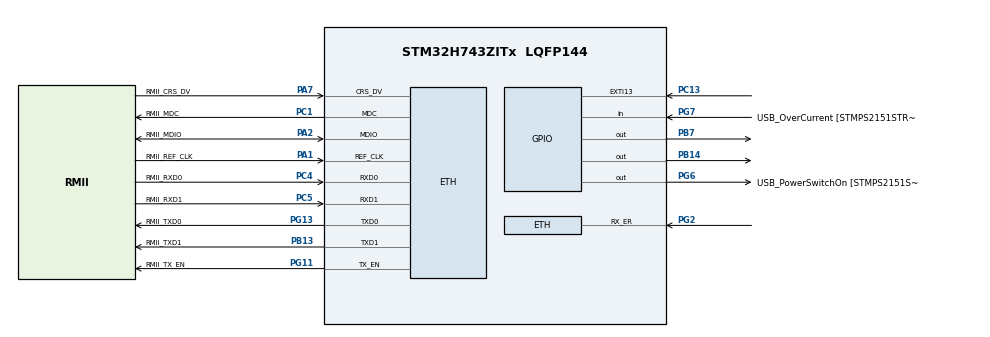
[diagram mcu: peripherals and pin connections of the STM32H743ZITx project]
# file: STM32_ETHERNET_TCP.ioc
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CORTEX_M7.AccessPermission-Cortex_Memory_Protection_Unit_Region0_Settings=MPU_REGION_NO_ACCESS
CORTEX_M7.AccessPermission-Cortex_Memory_Protection_Unit_Region1_Settings=MPU_REGION_FULL_ACCESS
CORTEX_M7.BaseAddress-Cortex_Memory_Protection_Unit_Region0_Settings=0x00000000
CORTEX_M7.BaseAddress-Cortex_Memory_Protection_Unit_Region1_Settings=0x30000000
CORTEX_M7.CPU_DCache=Disabled
CORTEX_M7.CPU_ICache=Disabled
CORTEX_M7.DisableExec-Cortex_Memory_Protection_Unit_Region0_Settings=MPU_INSTRUCTION_ACCESS_DISABLE
CORTEX_M7.DisableExec-Cortex_Memory_Protection_Unit_Region1_Settings=MPU_INSTRUCTION_ACCESS_DISABLE
CORTEX_M7.Enable-Cortex_Memory_Protection_Unit_Region0_Settings=MPU_REGION_ENABLE
CORTEX_M7.Enable-Cortex_Memory_Protection_Unit_Region1_Settings=MPU_REGION_ENABLE
CORTEX_M7.IsBufferable-Cortex_Memory_Protection_Unit_Region0_Settings=MPU_ACCESS_NOT_BUFFERABLE
CORTEX_M7.IsBufferable-Cortex_Memory_Protection_Unit_Region1_Settings=MPU_ACCESS_NOT_BUFFERABLE
CORTEX_M7.IsCacheable-Cortex_Memory_Protection_Unit_Region0_Settings=MPU_ACCESS_NOT_CACHEABLE
CORTEX_M7.IsCacheable-Cortex_Memory_Protection_Unit_Region1_Settings=MPU_ACCESS_NOT_CACHEABLE
CORTEX_M7.IsShareable-Cortex_Memory_Protection_Unit_Region0_Settings=MPU_ACCESS_SHAREABLE
CORTEX_M7.IsShareable-Cortex_Memory_Protection_Unit_Region1_Settings=MPU_ACCESS_SHAREABLE
CORTEX_M7.MPU_Control=MPU_PRIVILEGED_DEFAULT
CORTEX_M7.Size-Cortex_Memory_Protection_Unit_Region0_Settings=MPU_REGION_SIZE_4GB
CORTEX_M7.Size-Cortex_Memory_Protection_Unit_Region1_Settings=MPU_REGION_SIZE_64KB
CORTEX_M7.SubRegionDisable-Cortex_Memory_Protection_Unit_Region0_Settings=0x87
CORTEX_M7.SubRegionDisable-Cortex_Memory_Protection_Unit_Region1_Settings=0x00
CORTEX_M7.TypeExtField-Cortex_Memory_Protection_Unit_Region0_Settings=MPU_TEX_LEVEL0
CORTEX_M7.TypeExtField-Cortex_Memory_Protection_Unit_Region1_Settings=MPU_TEX_LEVEL1
CORTEX_M7.default_mode_Activation=1
ETH.ETH_RX_DESC_CNT=4
ETH.ETH_TX_DESC_CNT=4
ETH.MACAddr=00\:80\:E1\:00\:00\:00
ETH.MediaInterface=HAL_ETH_RMII_MODE
ETH.RxBuffAddress=0x30000100
ETH.RxBuffLen=1536
ETH.RxDescAddress=0x30000000
ETH.TxDescAddress=0x30000080
FREERTOS.Tasks01=defaultTask,24,1024,StartDefaultTask,Default,NULL,Dynamic,NULL,NULL
FREERTOS.configGENERATE_RUN_TIME_STATS=1
FREERTOS.configMINIMAL_STACK_SIZE=1024
FREERTOS.configTOTAL_HEAP_SIZE=65536
FREERTOS.configUSE_NEWLIB_REENTRANT=1
FREERTOS.configUSE_STATS_FORMATTING_FUNCTIONS=1
LWIP.BSP.number=1
LWIP.DEFAULT_THREAD_STACKSIZE=1024
LWIP.GATEWAY_ADDRESS=192.168.000.001
LWIP.IP_ADDRESS=192.168.000.200
LWIP.LWIP_DHCP=0
LWIP.LWIP_NETIF_LINK_CALLBACK=1
LWIP.LWIP_RAM_HEAP_POINTER=0x30008000
LWIP.MEM_SIZE=16384
LWIP.NETMASK_ADDRESS=255.255.255.000
LWIP.TCPIP_THREAD_STACKSIZE=4096
LWIP.TCP_SND_QUEUELEN=9
LWIP.Version=v2.2.1_Cube
LWIP0.BSP.STBoard=false
LWIP0.BSP.api=BSP_COMPONENT_DRIVER
LWIP0.BSP.component=LAN8742
LWIP0.BSP.instance=LAN8742
LWIP0.BSP.name=Driver_PHY
LWIP0.BSP.semaphore=S_LAN8742
LWIP0.BSP.solution=LAN8742
Mcu.Family=STM32H7
Mcu.Name=STM32H743ZITx
Mcu.Package=LQFP144
NUCLEO-H743ZI.BUTTON=1
NUCLEO-H743ZI.LD1=true
NUCLEO-H743ZI.LD2=true
NUCLEO-H743ZI.LD3=true
NUCLEO-H743ZI.VCP=true
NVIC.EXTI15_10_IRQn=true\:5\:0\:false\:false\:true\:true\:false\:true\:true
NVIC.PriorityGroup=NVIC_PRIORITYGROUP_4
NVIC.TIM17_IRQn=true\:15\:0\:false\:false\:true\:false\:false\:true\:true
NVIC.TimeBase=TIM17_IRQn
NVIC.TimeBaseIP=TIM17
PA1.GPIO_Label=RMII_REF_CLK
PA1.Mode=RMII
PA1.Signal=ETH_REF_CLK
PA10.GPIO_Label=USB_ID
PA10.Signal=USB_OTG_FS_ID
PA11.GPIO_Label=USB_DM
PA11.Signal=USB_OTG_FS_DM
PA12.GPIO_Label=USB_DP
PA12.Signal=USB_OTG_FS_DP
PA13\ (JTMS/SWDIO).GPIO_Label=TMS
PA13\ (JTMS/SWDIO).Signal=DEBUG_JTMS-SWDIO
PA14\ (JTCK/SWCLK).GPIO_Label=TCK
PA14\ (JTCK/SWCLK).Signal=DEBUG_JTCK-SWCLK
PA2.GPIO_Label=RMII_MDIO
PA2.Mode=RMII
PA2.Signal=ETH_MDIO
PA7.GPIO_Label=RMII_CRS_DV
PA7.Mode=RMII
PA7.Signal=ETH_CRS_DV
PA8.GPIO_Label=USB_SOF [TP1]
PA8.Signal=USB_OTG_FS_SOF
PA9.GPIO_Label=USB_VBUS
PA9.Signal=USB_OTG_FS_VBUS
PB13.GPIO_Label=RMII_TXD1
PB13.Mode=RMII
PB13.Signal=ETH_TXD1
PB14.Signal=GPIO_Output
PB3\ (JTDO/TRACESWO).GPIO_Label=SWO
PB3\ (JTDO/TRACESWO).Signal=DEBUG_JTDO-SWO
PB7.Signal=GPIO_Output
PC1.GPIO_Label=RMII_MDC
PC1.Mode=RMII
PC1.Signal=ETH_MDC
PC13.Signal=GPXTI13
PC14-OSC32_IN\ (OSC32_IN).Signal=RCC_OSC32_IN
PC15-OSC32_OUT\ (OSC32_OUT).Signal=RCC_OSC32_OUT
PC4.GPIO_Label=RMII_RXD0
PC4.Mode=RMII
PC4.Signal=ETH_RXD0
PC5.GPIO_Label=RMII_RXD1
PC5.Mode=RMII
PC5.Signal=ETH_RXD1
PD8.Signal=USART3_TX
PD9.Signal=USART3_RX
PG11.GPIO_Label=RMII_TX_EN
PG11.Mode=RMII
PG11.Signal=ETH_TX_EN
PG13.GPIO_Label=RMII_TXD0
PG13.Mode=RMII
PG13.Signal=ETH_TXD0
PG2.Mode=RMII
PG2.Signal=ETH_RX_ER
PG6.GPIO_Label=USB_PowerSwitchOn [STMPS2151STR_EN]
PG6.Signal=GPIO_Output
PG7.GPIO_Label=USB_OverCurrent [STMPS2151STR_FAULT]
PG7.Signal=GPIO_Input
PH0-OSC_IN\ (PH0).GPIO_Label=MCO
PH0-OSC_IN\ (PH0).Signal=RCC_OSC_IN
ProjectManager.HeapSize=0x200
ProjectManager.StackSize=0x400
ProjectManager.TargetToolchain=STM32CubeIDE
RCC.48MHZClocksFreq_Value=24000000
RCC.ADCFreq_Value=129000000
RCC.AHBFreq_Value=216000000
RCC.APB1CLKDivider=RCC_HCLK_DIV4
RCC.APB1Freq_Value=120000000
RCC.APB1TimFreq_Value=108000000
RCC.APB2CLKDivider=RCC_HCLK_DIV2
RCC.APB2Freq_Value=120000000
RCC.APB2TimFreq_Value=216000000
RCC.APB3Freq_Value=120000000
RCC.APB4Freq_Value=120000000
RCC.CortexFreq_Value=480000000
RCC.D1PPRE=RCC_APB3_DIV2
RCC.D2PPRE1=RCC_APB1_DIV2
RCC.D2PPRE2=RCC_APB2_DIV2
RCC.D3PPRE=RCC_APB4_DIV2
RCC.DIVM1=4
RCC.DIVN1=60
RCC.DIVQ1=4
RCC.HCLKFreq_Value=240000000
RCC.HPRE=RCC_HCLK_DIV2
RCC.HSE_VALUE=8000000
RCC.HSI_VALUE=64000000
RCC.PLLFRACN=0
RCC.PLLM=25
RCC.PLLMUL=RCC_PLL_MUL9
RCC.PLLN=432
RCC.PLLQ=9
RCC.PRESCALERUSB=RCC_USBCLKSOURCE_PLL_DIV1_5
RCC.SYSCLKFreq_VALUE=480000000
RCC.SYSCLKSource=RCC_SYSCLKSOURCE_PLLCLK
RCC.SYSCLKSourceVirtual=RCC_SYSCLKSOURCE_PLLCLK
RCC.USBFreq_Value=240000000
RCC.VCOOutputFreq_Value=432000000
VP_FREERTOS_VS_CMSIS_V2.Mode=CMSIS_V2
VP_LWIP_VS_Enabled.Mode=Enabled
VP_MEMORYMAP_VS_MEMORYMAP.Mode=CurAppReg
VP_NUCLEO-H743ZI_VS_BSP_COMMON.Mode=COMMON
VP_SYS_VS_tim17.Mode=TIM17
board=NUCLEO-H743ZI

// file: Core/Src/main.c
/* USER CODE BEGIN Header */
/**
  ******************************************************************************
  * @file           : main.c
  * @brief          : Main program body
  ******************************************************************************
  * @attention
  *
  * Copyright (c) 2026 STMicroelectronics.
  * All rights reserved.
  *
  * This software is licensed under terms that can be found in the LICENSE file
  * in the root directory of this software component.
  * If no LICENSE file comes with this software, it is provided AS-IS.
  *
  ******************************************************************************
  */
/* USER CODE END Header */
#include "main.h"
#include "FreeRTOS.h"
#include "cmsis_os2.h"
#include "lwip.h"

/* USER CODE BEGIN Includes */
#include "led_manager.h"
#include "tcp_server.h"
#include "iec104/iec104_app.h"
/* USER CODE END Includes */

COM_InitTypeDef BspCOMInit;

/* One-shot initialization task. */
static const osThreadAttr_t initTask_attributes = {
  .name = "InitTask",
  .stack_size = 1024 * 4,
  .priority = (osPriority_t) osPriorityNormal,
};

void SystemClock_Config(void);
static void MPU_Config(void);
static void MX_GPIO_Init(void);
static void StartInitTask(void *argument);

int main(void)
{

  /* MPU Configuration--------------------------------------------------------*/
  MPU_Config();

  /* MCU Configuration--------------------------------------------------------*/

  /* Reset of all peripherals, Initializes the Flash interface and the Systick. */
  HAL_Init();

  /* Configure the system clock */
  SystemClock_Config();

  /* Initialize all configured peripherals */
  MX_GPIO_Init();

  /* Init scheduler */
  osKernelInitialize();

  /* Create the thread(s) */
  /* Create the one-shot initialization task. */
  (void)osThreadNew(StartInitTask, NULL, &initTask_attributes);

  /* Initialize leds */
  BSP_LED_Init(LED_GREEN);
  BSP_LED_Init(LED_BLUE);
  BSP_LED_Init(LED_RED);

  /* Initialize USER push-button, will be used to trigger an interrupt each time it's pressed.*/
  BSP_PB_Init(BUTTON_USER, BUTTON_MODE_EXTI);

  /* Initialize COM1 port (115200, 8 bits (7-bit data + 1 stop bit), no parity */
  BspCOMInit.BaudRate   = 115200;
  BspCOMInit.WordLength = COM_WORDLENGTH_8B;
  BspCOMInit.StopBits   = COM_STOPBITS_1;
  BspCOMInit.Parity     = COM_PARITY_NONE;
  BspCOMInit.HwFlowCtl  = COM_HWCONTROL_NONE;
  if (BSP_COM_Init(COM1, &BspCOMInit) != BSP_ERROR_NONE)
  {
    Error_Handler();
  }

  /* Start scheduler */
  osKernelStart();

  /* We should never get here as control is now taken by the scheduler */

  /* Infinite loop */
  while (1)
  {

  }
}

void SystemClock_Config(void)
{
  RCC_OscInitTypeDef RCC_OscInitStruct = {0};
  RCC_ClkInitTypeDef RCC_ClkInitStruct = {0};

  /** Supply configuration update enable
  */
  HAL_PWREx_ConfigSupply(PWR_LDO_SUPPLY);

  /** Configure the main internal regulator output voltage
  */
  __HAL_PWR_VOLTAGESCALING_CONFIG(PWR_REGULATOR_VOLTAGE_SCALE0);

  while(!__HAL_PWR_GET_FLAG(PWR_FLAG_VOSRDY)) {}

  /** Initializes the RCC Oscillators according to the specified parameters
  * in the RCC_OscInitTypeDef structure.
  */
  RCC_OscInitStruct.OscillatorType = RCC_OSCILLATORTYPE_HSI;
  RCC_OscInitStruct.HSIState = RCC_HSI_DIV1;
  RCC_OscInitStruct.HSICalibrationValue = RCC_HSICALIBRATION_DEFAULT;
  RCC_OscInitStruct.PLL.PLLState = RCC_PLL_ON;
  RCC_OscInitStruct.PLL.PLLSource = RCC_PLLSOURCE_HSI;
  RCC_OscInitStruct.PLL.PLLM = 4;
  RCC_OscInitStruct.PLL.PLLN = 60;
  RCC_OscInitStruct.PLL.PLLP = 2;
  RCC_OscInitStruct.PLL.PLLQ = 4;
  RCC_OscInitStruct.PLL.PLLR = 2;
  RCC_OscInitStruct.PLL.PLLRGE = RCC_PLL1VCIRANGE_3;
  RCC_OscInitStruct.PLL.PLLVCOSEL = RCC_PLL1VCOWIDE;
  RCC_OscInitStruct.PLL.PLLFRACN = 0;
  if (HAL_RCC_OscConfig(&RCC_OscInitStruct) != HAL_OK)
  {
    Error_Handler();
  }

  /** Initializes the CPU, AHB and APB buses clocks
  */
  RCC_ClkInitStruct.ClockType = RCC_CLOCKTYPE_HCLK|RCC_CLOCKTYPE_SYSCLK
                              |RCC_CLOCKTYPE_PCLK1|RCC_CLOCKTYPE_PCLK2
                              |RCC_CLOCKTYPE_D3PCLK1|RCC_CLOCKTYPE_D1PCLK1;
  RCC_ClkInitStruct.SYSCLKSource = RCC_SYSCLKSOURCE_PLLCLK;
  RCC_ClkInitStruct.SYSCLKDivider = RCC_SYSCLK_DIV1;
  RCC_ClkInitStruct.AHBCLKDivider = RCC_HCLK_DIV2;
  RCC_ClkInitStruct.APB3CLKDivider = RCC_APB3_DIV2;
  RCC_ClkInitStruct.APB1CLKDivider = RCC_APB1_DIV2;
  RCC_ClkInitStruct.APB2CLKDivider = RCC_APB2_DIV2;
  RCC_ClkInitStruct.APB4CLKDivider = RCC_APB4_DIV2;

  if (HAL_RCC_ClockConfig(&RCC_ClkInitStruct, FLASH_LATENCY_4) != HAL_OK)
  {
    Error_Handler();
  }
}

static void MX_GPIO_Init(void)
{
  GPIO_InitTypeDef GPIO_InitStruct = {0};

  /* GPIO Ports Clock Enable */
  __HAL_RCC_GPIOC_CLK_ENABLE();
  __HAL_RCC_GPIOH_CLK_ENABLE();
  __HAL_RCC_GPIOA_CLK_ENABLE();
  __HAL_RCC_GPIOB_CLK_ENABLE();
  __HAL_RCC_GPIOG_CLK_ENABLE();

  /*Configure GPIO pin Output Level */
  HAL_GPIO_WritePin(USB_PowerSwitchOn_GPIO_Port, USB_PowerSwitchOn_Pin, GPIO_PIN_RESET);

  /*Configure GPIO pin : USB_PowerSwitchOn_Pin */
  GPIO_InitStruct.Pin = USB_PowerSwitchOn_Pin;
  GPIO_InitStruct.Mode = GPIO_MODE_OUTPUT_PP;
  GPIO_InitStruct.Pull = GPIO_NOPULL;
  GPIO_InitStruct.Speed = GPIO_SPEED_FREQ_LOW;
  HAL_GPIO_Init(USB_PowerSwitchOn_GPIO_Port, &GPIO_InitStruct);

  /*Configure GPIO pin : USB_OverCurrent_Pin */
  GPIO_InitStruct.Pin = USB_OverCurrent_Pin;
  GPIO_InitStruct.Mode = GPIO_MODE_INPUT;
  GPIO_InitStruct.Pull = GPIO_NOPULL;
  HAL_GPIO_Init(USB_OverCurrent_GPIO_Port, &GPIO_InitStruct);

  /*Configure GPIO pins : USB_SOF_Pin USB_ID_Pin USB_DM_Pin USB_DP_Pin */
  GPIO_InitStruct.Pin = USB_SOF_Pin|USB_ID_Pin|USB_DM_Pin|USB_DP_Pin;
  GPIO_InitStruct.Mode = GPIO_MODE_AF_PP;
  GPIO_InitStruct.Pull = GPIO_NOPULL;
  GPIO_InitStruct.Speed = GPIO_SPEED_FREQ_LOW;
  GPIO_InitStruct.Alternate = GPIO_AF10_OTG1_FS;
  HAL_GPIO_Init(GPIOA, &GPIO_InitStruct);

}

/* USER CODE BEGIN Header_StartInitTask */
/**
  * @brief  Initialize application services, then terminate this task.
  * @param  argument: Not used
  * @retval None
  */
/* USER CODE END Header_StartInitTask */
static void StartInitTask(void *argument)
{
  (void)argument;
  /* Initialize networking while the scheduler is running. */
  MX_LWIP_Init();
  /* USER CODE BEGIN 5 */
  LedManager_Init();
  if (!IEC104_AppInit())
    Error_Handler();
  /* TcpServer_Init(); Port 3001 is not used while IEC-104 is active. */

  /* Initialization is complete; other tasks run independently. */
  osThreadExit();
  /* USER CODE END 5 */
}

 /* MPU Configuration */

void MPU_Config(void)
{
  MPU_Region_InitTypeDef MPU_InitStruct = {0};

  /* Disables the MPU */
  HAL_MPU_Disable();

  /** Initializes and configures the Region and the memory to be protected
  */
  MPU_InitStruct.Enable = MPU_REGION_ENABLE;
  MPU_InitStruct.Number = MPU_REGION_NUMBER0;
  MPU_InitStruct.BaseAddress = 0x0;
  MPU_InitStruct.Size = MPU_REGION_SIZE_4GB;
  MPU_InitStruct.SubRegionDisable = 0x87;
  MPU_InitStruct.TypeExtField = MPU_TEX_LEVEL0;
  MPU_InitStruct.AccessPermission = MPU_REGION_NO_ACCESS;
  MPU_InitStruct.DisableExec = MPU_INSTRUCTION_ACCESS_DISABLE;
  MPU_InitStruct.IsShareable = MPU_ACCESS_SHAREABLE;
  MPU_InitStruct.IsCacheable = MPU_ACCESS_NOT_CACHEABLE;
  MPU_InitStruct.IsBufferable = MPU_ACCESS_NOT_BUFFERABLE;

  HAL_MPU_ConfigRegion(&MPU_InitStruct);
  /* Enables the MPU */
  HAL_MPU_Enable(MPU_PRIVILEGED_DEFAULT);

}

void HAL_TIM_PeriodElapsedCallback(TIM_HandleTypeDef *htim)
{
  if (htim->Instance == TIM17)
  {
    HAL_IncTick();
  }
}

void Error_Handler(void)
{
  __disable_irq();
  while (1)
  {
  }
}

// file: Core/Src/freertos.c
/* USER CODE BEGIN Header */
/**
  ******************************************************************************
  * File Name          : freertos.c
  * Description        : Code for freertos applications
  ******************************************************************************
  * @attention
  *
  * Copyright (c) 2026 STMicroelectronics.
  * All rights reserved.
  *
  * This software is licensed under terms that can be found in the LICENSE file
  * in the root directory of this software component.
  * If no LICENSE file comes with this software, it is provided AS-IS.
  *
  ******************************************************************************
  */
/* USER CODE END Header */

#include "FreeRTOS.h"
#include "task.h"
#include "main.h"

/* Hook prototypes */
void configureTimerForRunTimeStats(void);
unsigned long getRunTimeCounterValue(void);

/* USER CODE BEGIN 1 */
/* Functions needed when configGENERATE_RUN_TIME_STATS is on */
__weak void configureTimerForRunTimeStats(void)
{

}

__weak unsigned long getRunTimeCounterValue(void)
{
return 0;
}
/* USER CODE END 1 */

/* USER CODE BEGIN Application */

void vApplicationStackOverflowHook(TaskHandle_t xTask, char *pcTaskName)
{
  (void)xTask;
  taskDISABLE_INTERRUPTS();
  printf("FATAL: stack overflow in task %s\r\n",
         (pcTaskName != NULL) ? pcTaskName : "unknown");
  for (;;)
  {
  }
}

void vApplicationMallocFailedHook(void)
{
  taskDISABLE_INTERRUPTS();
  for (;;)
  {
  }
}

/* USER CODE END Application */
